# ATtiny13A device description
Architecture: AVR8; Family: tinyAVR
Registers are 8-bit, access not given, no defined reset value unless marked. A register's access mark holds for its fields unless they carry their own. Offsets are from the block's base; [hi:lo] are bit positions.

## LOCKBIT — Lockbits
Instances: LOCKBIT 0 in lockbits
0x00 LOCKBIT
  [1:0] LB — Memory Lock
    0=PROG_VER_DISABLED (Further programming and verification disabled); 2=PROG_DISABLED (Further programming disabled); 3=NO_LOCK (No memory lock features enabled)

## ADC — Analog-to-Digital Converter
Instances: ADC 0x00
0x23 ADCSRB — ADC Control and Status Register B
  [2:0] ADTS — ADC Auto Trigger Sources
    0=Free Running mode; 1=Analog Comparator; 2=External Interrupt Request 0; 3=Timer/Counter0 Compare Match A; 4=Timer/Counter0 Overflow; 5=Timer/Counter1 Compare Match B; 6=Timer/Counter1 Overflow; 7=Timer/Counter1 Capture Event
0x24 ADC 16-bit — ADC Data Register Bytes
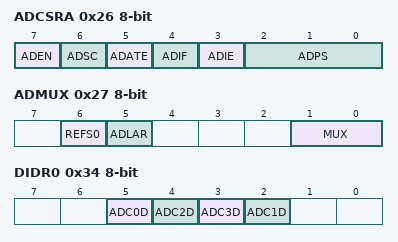
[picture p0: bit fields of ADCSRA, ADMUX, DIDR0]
0x26 ADCSRA — The ADC Control and Status register
  [7] ADEN — ADC Enable
  [6] ADSC — ADC Start Conversion
  [5] ADATE — ADC Auto Trigger Enable
  [4] ADIF — ADC Interrupt Flag
  [3] ADIE — ADC Interrupt Enable
  [2:0] ADPS — ADC Prescaler Select Bits
    0=2; 1=2; 2=4; 3=8; 4=16; 5=32; 6=64; 7=128
0x27 ADMUX — The ADC multiplexer Selection Register
  [6] REFS0 — Reference Selection Bit 0
  [5] ADLAR — Left Adjust Result
  [1:0] MUX — Analog Channel and Gain Selection Bits
0x34 DIDR0 — Digital Input Disable Register 0
  [5] ADC0D — ADC0 Digital input Disable
  [4] ADC2D — ADC2 Digital input Disable
  [3] ADC3D — ADC3 Digital input Disable
  [2] ADC1D — ADC2 Digital input Disable

## AC — Analog Comparator
Instances: AC 0x00
0x23 ADCSRB — ADC Control and Status Register B
  [6] ACME — Analog Comparator Multiplexer Enable
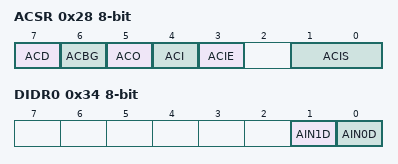
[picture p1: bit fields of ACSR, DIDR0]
0x28 ACSR — Analog Comparator Control And Status Register
  [7] ACD — Analog Comparator Disable
  [6] ACBG — Analog Comparator Bandgap Select
  [5] ACO — Analog Compare Output
  [4] ACI — Analog Comparator Interrupt Flag
  [3] ACIE — Analog Comparator Interrupt Enable
  [1:0] ACIS — Analog Comparator Interrupt Mode Select bits
    0=Interrupt on Toggle; 2=Interrupt on Falling Edge; 3=Interrupt on Rising Edge
0x34 DIDR0
  [1] AIN1D — AIN1 Digital Input Disable
  [0] AIN0D — AIN0 Digital Input Disable

## EEPROM
Instances: EEPROM 0x00
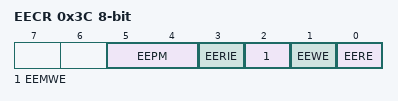
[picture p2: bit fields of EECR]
0x3C EECR — EEPROM Control Register
  [5:4] EEPM
    0=Erase and Write in one operation; 1=Erase Only; 2=Write Only
  [3] EERIE — EEProm Ready Interrupt Enable
  [2] EEMWE — EEPROM Master Write Enable
  [1] EEWE — EEPROM Write Enable
  [0] EERE — EEPROM Read Enable
0x3D EEDR — EEPROM Data Register
0x3E EEAR bits used 5:0 — EEPROM Read/Write Access

## PORTB — I/O Port
Instances: PORTB 0x00
0x36 PINB bits used 5:0 — Input Pins, Port B
0x37 DDRB bits used 5:0 — Data Direction Register, Port B
0x38 PORTB bits used 5:0 — Data Register, Port B

## EXINT — External Interrupts
Instances: EXINT 0x00
0x35 PCMSK bits used 5:0 — Pin Change Enable Mask
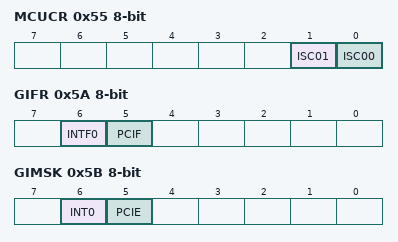
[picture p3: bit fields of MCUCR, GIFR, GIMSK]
0x55 MCUCR — MCU Control Register
  [1] ISC01 — Interrupt Sense Control 0 Bit 1
  [0] ISC00 — Interrupt Sense Control 0 Bit 0
    0=Low Level of INTX; 1=Any Logical Change of INTX; 2=Falling Edge of INTX; 3=Rising Edge of INTX
0x5A GIFR — General Interrupt Flag register
  [6] INTF0 — External Interrupt Flag 0
  [5] PCIF — Pin Change Interrupt Flag
0x5B GIMSK — General Interrupt Mask Register
  [6] INT0 — External Interrupt Request 0 Enable
  [5] PCIE — Pin Change Interrupt Enable

## TC0 (TC8 module) — Timer/Counter, 8-bit
Instances: TC0 0x00
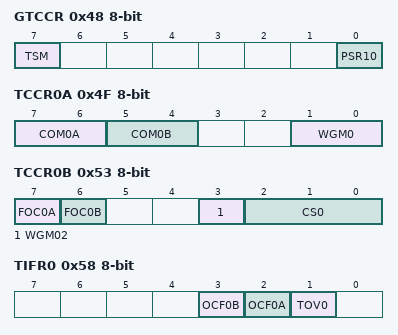
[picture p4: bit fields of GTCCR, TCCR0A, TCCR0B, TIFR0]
0x48 GTCCR — General Timer Conuter Register
  [7] TSM — Timer/Counter Synchronization Mode
  [0] PSR10 — Prescaler Reset Timer/Counter0
0x49 OCR0B — Timer/Counter0 Output Compare Register
0x4F TCCR0A — Timer/Counter Control Register A
  [7:6] COM0A — Compare Match Output A Mode
  [5:4] COM0B — Compare Match Output B Mode
  [1:0] WGM0 — Waveform Generation Mode
0x52 TCNT0 — Timer/Counter0
0x53 TCCR0B — Timer/Counter Control Register B
  [7] FOC0A — Force Output Compare A
  [6] FOC0B — Force Output Compare B
  [3] WGM02 — Waveform Generation Mode
  [2:0] CS0 — Clock Select
    0=No Clock Source (Stopped); 1=Running, No Prescaling; 2=Running, CLK/8; 3=Running, CLK/64; 4=Running, CLK/256; 5=Running, CLK/1024; 6=Running, ExtClk Tx Falling Edge; 7=Running, ExtClk Tx Rising Edge
0x56 OCR0A — Timer/Counter0 Output Compare Register
0x58 TIFR0 — Timer/Counter0 Interrupt Flag register
  [3] OCF0B — Timer/Counter0 Output Compare Flag 0B
  [2] OCF0A — Timer/Counter0 Output Compare Flag 0A
  [1] TOV0 — Timer/Counter0 Overflow Flag
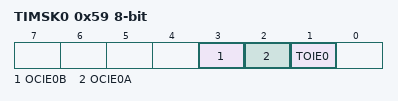
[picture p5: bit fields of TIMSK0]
0x59 TIMSK0 — Timer/Counter0 Interrupt Mask Register
  [3] OCIE0B — Timer/Counter0 Output Compare Match B Interrupt Enable
  [2] OCIE0A — Timer/Counter0 Output Compare Match A Interrupt Enable
  [1] TOIE0 — Timer/Counter0 Overflow Interrupt Enable

## WDT — Watchdog Timer
Instances: WDT 0x00
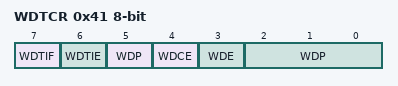
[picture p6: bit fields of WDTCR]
0x41 WDTCR — Watchdog Timer Control Register
  [7] WDTIF — Watchdog Timeout Interrupt Flag
  [6] WDTIE — Watchdog Timeout Interrupt Enable
  [4] WDCE — Watchdog Change Enable
  [3] WDE — Watch Dog Enable
  [5,2:0] WDP — Watchdog Timer Prescaler Bits
    0=Oscillator Cycles 2K; 1=Oscillator Cycles 4K; 2=Oscillator Cycles 8K; 3=Oscillator Cycles 16K; 4=Oscillator Cycles 32K; 5=Oscillator Cycles 64K; 6=Oscillator Cycles 128K; 7=Oscillator Cycles 256K; 8=Oscillator Cycles 512K; 9=Oscillator Cycles 1024K

## CPU — CPU Registers
Instances: CPU 0x00
Parameters: CORE_VERSION=V2, NEW_INSTRUCTIONS=lpm rd,z+
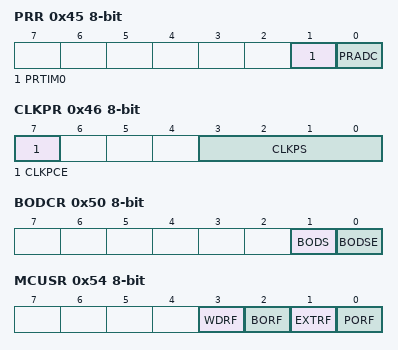
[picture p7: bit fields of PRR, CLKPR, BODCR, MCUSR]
0x45 PRR — Power Reduction Register
  [1] PRTIM0 — Power Reduction Timer/Counter0
  [0] PRADC — Power Reduction ADC
0x46 CLKPR — Clock Prescale Register
  [7] CLKPCE — Clock Prescaler Change Enable
  [3:0] CLKPS — Clock Prescaler Select Bits
    0=1; 1=2; 2=4; 3=8; 4=16; 5=32; 6=64; 7=128; 8=256
0x4E DWDR — Debug Wire Data Register
0x50 BODCR — BOD Control Register
  [1] BODS — BOD Power-Down in Power-Down Sleep
  [0] BODSE — BOD Power-Down Sleep Enable
0x51 OSCCAL — Oscillator Calibration Register
  [7:0] OSCCAL — Oscillator Calibration
0x54 MCUSR — MCU Status register
  [3] WDRF — Watchdog Reset Flag
  [2] BORF — Brown-out Reset Flag
  [1] EXTRF — External Reset Flag
  [0] PORF — Power-On Reset Flag
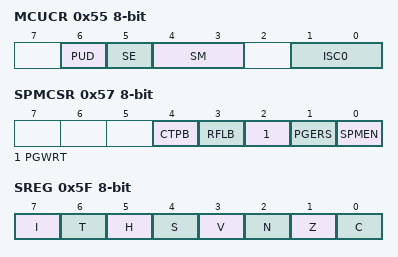
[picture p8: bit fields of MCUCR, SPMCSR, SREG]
0x55 MCUCR — MCU Control Register
  [6] PUD — Pull-up Disable
  [5] SE — Sleep Enable
  [4:3] SM — Sleep Mode Select Bits
    0=IDLE; 1=ADC (ADC Noise Reduction (If Available)); 2=PDOWN (Power Down)
  [1:0] ISC0 — Interrupt Sense Control 0 bits
    0=Low Level of INTX; 1=Any Logical Change in INTX; 2=Falling Edge of INTX; 3=Rising Edge of INTX
0x57 SPMCSR — Store Program Memory Control and Status Register
  [4] CTPB — Clear Temporary Page Buffer
  [3] RFLB — Read Fuse and Lock Bits
  [2] PGWRT — Page Write
  [1] PGERS — Page Erase
  [0] SPMEN — Store program Memory Enable
0x5D SPL — Stack Pointer Low Byte
0x5F SREG — Status Register
  [7] I — Global Interrupt Enable
  [6] T — Bit Copy Storage
  [5] H — Half Carry Flag
  [4] S — Sign Bit
  [3] V — Two's Complement Overflow Flag
  [2] N — Negative Flag
  [1] Z — Zero Flag
  [0] C — Carry Flag
Value list OSCCAL_VALUE_ADDRESSES: 0=9_6_MHz; 1=4_8_MHz
